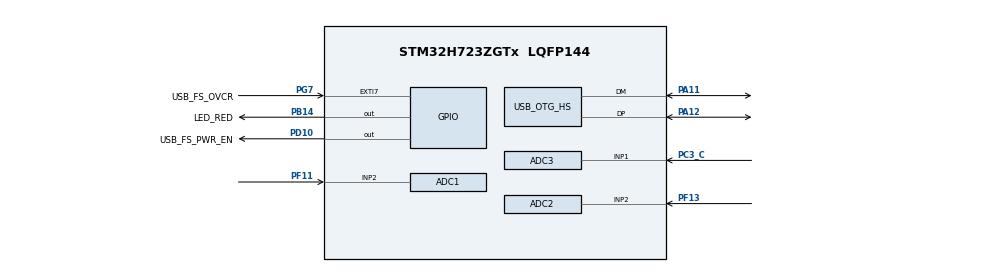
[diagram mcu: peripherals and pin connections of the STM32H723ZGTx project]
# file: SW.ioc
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ADC1.Channel-1\#ChannelRegularConversion=ADC_CHANNEL_2
ADC1.ClockPrescaler=ADC_CLOCK_ASYNC_DIV64
ADC1.NbrOfConversionFlag=1
ADC1.OffsetNumber-1\#ChannelRegularConversion=ADC_OFFSET_NONE
ADC1.OffsetSignedSaturation-1\#ChannelRegularConversion=DISABLE
ADC1.Rank-1\#ChannelRegularConversion=1
ADC1.Resolution=ADC_RESOLUTION_12B
ADC1.SamplingTime-1\#ChannelRegularConversion=ADC_SAMPLETIME_1CYCLE_5
ADC1.master=1
ADC2.Channel-0\#ChannelRegularConversion=ADC_CHANNEL_2
ADC2.ClockPrescaler=ADC_CLOCK_ASYNC_DIV64
ADC2.NbrOfConversionFlag=1
ADC2.OffsetNumber-0\#ChannelRegularConversion=ADC_OFFSET_NONE
ADC2.OffsetSignedSaturation-0\#ChannelRegularConversion=DISABLE
ADC2.Rank-0\#ChannelRegularConversion=1
ADC2.SamplingTime-0\#ChannelRegularConversion=ADC_SAMPLETIME_1CYCLE_5
ADC3.Channel-0\#ChannelRegularConversion=ADC_CHANNEL_1
ADC3.ClockPrescaler=ADC_CLOCK_ASYNC_DIV64
ADC3.NbrOfConversionFlag=1
ADC3.OffsetNumber-0\#ChannelRegularConversion=ADC_OFFSET_NONE
ADC3.OffsetSaturation-0\#ChannelRegularConversion=DISABLE
ADC3.OffsetSign-0\#ChannelRegularConversion=ADC3_OFFSET_SIGN_NEGATIVE
ADC3.OffsetSignedSaturation-0\#ChannelRegularConversion=DISABLE
ADC3.Rank-0\#ChannelRegularConversion=1
ADC3.SamplingTime-0\#ChannelRegularConversion=ADC3_SAMPLETIME_2CYCLES_5
FREERTOS.INCLUDE_uxTaskPriorityGet=0
FREERTOS.INCLUDE_vTaskDelete=0
FREERTOS.INCLUDE_vTaskPrioritySet=0
FREERTOS.MEMORY_ALLOCATION=0
FREERTOS.Tasks01=defaultTask,0,128,StartDefaultTask,Default,NULL,Dynamic,NULL,NULL
FREERTOS.configMAX_PRIORITIES=5
FREERTOS.configUSE_NEWLIB_REENTRANT=1
Mcu.Family=STM32H7
Mcu.Name=STM32H723ZGTx
Mcu.Package=LQFP144
NVIC.OTG_HS_IRQn=true\:5\:0\:false\:false\:true\:true\:false\:true
NVIC.PriorityGroup=NVIC_PRIORITYGROUP_4
NVIC.TIM6_DAC_IRQn=true\:5\:0\:false\:false\:true\:true\:true\:true
NVIC.TIM7_IRQn=true\:15\:0\:false\:false\:true\:false\:false\:true
NVIC.TimeBase=TIM7_IRQn
NVIC.TimeBaseIP=TIM7
PA1.GPIO_Label=RMII_REF_CLK
PA1.Signal=ETH_REF_CLK
PA10.GPIO_Label=USB_FS_ID
PA10.Signal=USB_OTG_HS_ID
PA11.Mode=Device_Only_FS
PA11.Signal=USB_OTG_HS_DM
PA12.Mode=Device_Only_FS
PA12.Signal=USB_OTG_HS_DP
PA13(JTMS/SWDIO).GPIO_Label=SWDIO
PA13(JTMS/SWDIO).Mode=Trace_Asynchronous_SW
PA13(JTMS/SWDIO).Signal=DEBUG_JTMS-SWDIO
PA14(JTCK/SWCLK).GPIO_Label=SWCLK
PA14(JTCK/SWCLK).Mode=Trace_Asynchronous_SW
PA14(JTCK/SWCLK).Signal=DEBUG_JTCK-SWCLK
PA2.GPIO_Label=RMII_MDIO
PA2.Signal=ETH_MDIO
PA7.GPIO_Label=RMII_CRS_DV
PA7.Signal=ETH_CRS_DV
PA9.GPIO_Label=USB_FS_VBUS
PA9.Signal=USB_OTG_HS_VBUS
PB13.GPIO_Label=RMII_TXD1
PB13.Signal=ETH_TXD1
PB14.GPIO_Label=LED_RED
PB14.Signal=GPIO_Output
PB3(JTDO/TRACESWO).GPIO_Label=SWO
PB3(JTDO/TRACESWO).Mode=Trace_Asynchronous_SW
PB3(JTDO/TRACESWO).Signal=DEBUG_JTDO-SWO
PC1.GPIO_Label=RMII_MDC
PC1.Signal=ETH_MDC
PC14-OSC32_IN.Mode=LSE-External-Oscillator
PC14-OSC32_IN.Signal=RCC_OSC32_IN
PC15-OSC32_OUT.Mode=LSE-External-Oscillator
PC15-OSC32_OUT.Signal=RCC_OSC32_OUT
PC3_C.Mode=IN1-Single-Ended
PC3_C.Signal=ADC3_INP1
PC4.GPIO_Label=RMII_RXD0
PC4.Signal=ETH_RXD0
PC5.GPIO_Label=RMII_RXD1
PC5.Signal=ETH_RXD1
PD10.GPIO_Label=USB_FS_PWR_EN
PD10.Signal=GPIO_Output
PD8.GPIO_Label=STLK_VCP_RX
PD8.Signal=USART3_TX
PD9.GPIO_Label=STLK_VCP_TX
PD9.Signal=USART3_RX
PF11.Mode=IN2-Single-Ended
PF11.Signal=ADC1_INP2
PF13.Mode=IN2-Single-Ended
PF13.Signal=ADC2_INP2
PG11.GPIO_Label=RMII_TX_EN
PG11.Signal=ETH_TX_EN
PG13.GPIO_Label=RMII_TXD0
PG13.Signal=ETH_TXD0
PG7.GPIO_Label=USB_FS_OVCR
PG7.Signal=GPXTI7
PH0-OSC_IN.GPIO_Label=MCO
PH0-OSC_IN.Mode=HSE-External-Clock-Source
PH0-OSC_IN.Signal=RCC_OSC_IN
PH1-OSC_OUT.Signal=RCC_OSC_OUT
ProjectManager.HeapSize=0x200
ProjectManager.StackSize=0x400
ProjectManager.TargetToolchain=STM32CubeIDE
RCC.ADCFreq_Value=48000000
RCC.APB1Freq_Value=48000000
RCC.APB2Freq_Value=48000000
RCC.APB3Freq_Value=48000000
RCC.APB4Freq_Value=48000000
RCC.CortexFreq_Value=192000000
RCC.D1PPRE=RCC_APB3_DIV2
RCC.D2PPRE1=RCC_APB1_DIV2
RCC.D2PPRE2=RCC_APB2_DIV2
RCC.D3PPRE=RCC_APB4_DIV2
RCC.DIVM1=1
RCC.DIVM2=1
RCC.DIVN1=24
RCC.DIVN2=24
RCC.DIVP1=1
RCC.DIVP2=4
RCC.DIVQ1=4
RCC.HCLKFreq_Value=96000000
RCC.HPRE=RCC_HCLK_DIV2
RCC.HSE_VALUE=8000000
RCC.PLL2FRACN=0
RCC.PLLFRACN=0
RCC.PLLSourceVirtual=RCC_PLLSOURCE_HSE
RCC.SYSCLKFreq_VALUE=192000000
RCC.SYSCLKSource=RCC_SYSCLKSOURCE_PLLCLK
RCC.USBCLockSelection=RCC_USBCLKSOURCE_HSI48
RCC.USBFreq_Value=48000000
TIM6.AutoReloadPreload=TIM_AUTORELOAD_PRELOAD_ENABLE
TIM6.Period=31999
TIM6.Prescaler=2999
USB_DEVICE.CLASS_NAME_HS=CDC
USB_DEVICE.VirtualMode=Cdc
USB_DEVICE.VirtualModeHS=Cdc_HS
USB_OTG_HS.VirtualMode-Device_Only_FS=Device_Only_FS
VP_FREERTOS_VS_CMSIS_V1.Mode=CMSIS_V1
VP_SYS_VS_tim7.Mode=TIM7
VP_TIM6_VS_ClockSourceINT.Mode=Enable_Timer
VP_USB_DEVICE_VS_USB_DEVICE_CDC_HS.Mode=CDC_HS
board=NUCLEO-H723ZG

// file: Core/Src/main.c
/* USER CODE BEGIN Header */
/**
  ******************************************************************************
  * @file           : main.c
  * @brief          : Main program body
  ******************************************************************************
  * @attention
  *
  * <h2><center>&copy; Copyright (c) 2021 STMicroelectronics.
  * All rights reserved.</center></h2>
  *
  * This software component is licensed by ST under Ultimate Liberty license
  * SLA0044, the "License"; You may not use this file except in compliance with
  * the License. You may obtain a copy of the License at:
  *                             www.st.com/SLA0044
  *
  ******************************************************************************
  */
/* USER CODE END Header */
#include "main.h"
#include "cmsis_os.h"
#include "usb_device.h"

/* USER CODE BEGIN Includes */
#include "voltmeter.h"
/* USER CODE END Includes */

ADC_HandleTypeDef hadc1;
ADC_HandleTypeDef hadc2;
ADC_HandleTypeDef hadc3;

TIM_HandleTypeDef htim6;

osThreadId defaultTaskHandle;

/* USER CODE BEGIN PV */

//TaskHandle_t* HandleTask1;

/* USER CODE END PV */

void SystemClock_Config(void);
void PeriphCommonClock_Config(void);
static void MX_GPIO_Init(void);
static void MX_ADC1_Init(void);
static void MX_ADC2_Init(void);
static void MX_ADC3_Init(void);
static void MX_TIM6_Init(void);
void StartDefaultTask(void const * argument);

int main(void)
{

  /* MCU Configuration--------------------------------------------------------*/

  /* Reset of all peripherals, Initializes the Flash interface and the Systick. */
  HAL_Init();

  /* Configure the system clock */
  SystemClock_Config();

/* Configure the peripherals common clocks */
  PeriphCommonClock_Config();

  /* Initialize all configured peripherals */
  MX_GPIO_Init();
  MX_ADC1_Init();
  MX_ADC2_Init();
  MX_ADC3_Init();
  MX_TIM6_Init();
  /* USER CODE BEGIN 2 */

  Voltmeter_init();

  /* USER CODE END 2 */

  /* Create the thread(s) */
  /* definition and creation of defaultTask */
  osThreadDef(defaultTask, StartDefaultTask, osPriorityNormal, 0, 128);
  defaultTaskHandle = osThreadCreate(osThread(defaultTask), NULL);

  /* USER CODE BEGIN RTOS_THREADS */
  vTaskStartScheduler();
  /* USER CODE END RTOS_THREADS */

  /* Start scheduler */
  //osKernelStart();

  /* We should never get here as control is now taken by the scheduler */
  /* Infinite loop */
  while (1)
  {

  }
}

void SystemClock_Config(void)
{
  RCC_OscInitTypeDef RCC_OscInitStruct = {0};
  RCC_ClkInitTypeDef RCC_ClkInitStruct = {0};

  /** Supply configuration update enable
  */
  HAL_PWREx_ConfigSupply(PWR_LDO_SUPPLY);
  /** Configure the main internal regulator output voltage
  */
  __HAL_PWR_VOLTAGESCALING_CONFIG(PWR_REGULATOR_VOLTAGE_SCALE2);

  while(!__HAL_PWR_GET_FLAG(PWR_FLAG_VOSRDY)) {}
  /** Macro to configure the PLL clock source
  */
  __HAL_RCC_PLL_PLLSOURCE_CONFIG(RCC_PLLSOURCE_HSE);
  /** Initializes the RCC Oscillators according to the specified parameters
  * in the RCC_OscInitTypeDef structure.
  */
  RCC_OscInitStruct.OscillatorType = RCC_OSCILLATORTYPE_HSI48|RCC_OSCILLATORTYPE_HSE;
  RCC_OscInitStruct.HSEState = RCC_HSE_BYPASS;
  RCC_OscInitStruct.HSI48State = RCC_HSI48_ON;
  RCC_OscInitStruct.PLL.PLLState = RCC_PLL_ON;
  RCC_OscInitStruct.PLL.PLLSource = RCC_PLLSOURCE_HSE;
  RCC_OscInitStruct.PLL.PLLM = 1;
  RCC_OscInitStruct.PLL.PLLN = 24;
  RCC_OscInitStruct.PLL.PLLP = 1;
  RCC_OscInitStruct.PLL.PLLQ = 4;
  RCC_OscInitStruct.PLL.PLLR = 2;
  RCC_OscInitStruct.PLL.PLLRGE = RCC_PLL1VCIRANGE_3;
  RCC_OscInitStruct.PLL.PLLVCOSEL = RCC_PLL1VCOWIDE;
  RCC_OscInitStruct.PLL.PLLFRACN = 0;
  if (HAL_RCC_OscConfig(&RCC_OscInitStruct) != HAL_OK)
  {
    Error_Handler();
  }
  /** Initializes the CPU, AHB and APB buses clocks
  */
  RCC_ClkInitStruct.ClockType = RCC_CLOCKTYPE_HCLK|RCC_CLOCKTYPE_SYSCLK
                              |RCC_CLOCKTYPE_PCLK1|RCC_CLOCKTYPE_PCLK2
                              |RCC_CLOCKTYPE_D3PCLK1|RCC_CLOCKTYPE_D1PCLK1;
  RCC_ClkInitStruct.SYSCLKSource = RCC_SYSCLKSOURCE_PLLCLK;
  RCC_ClkInitStruct.SYSCLKDivider = RCC_SYSCLK_DIV1;
  RCC_ClkInitStruct.AHBCLKDivider = RCC_HCLK_DIV2;
  RCC_ClkInitStruct.APB3CLKDivider = RCC_APB3_DIV2;
  RCC_ClkInitStruct.APB1CLKDivider = RCC_APB1_DIV2;
  RCC_ClkInitStruct.APB2CLKDivider = RCC_APB2_DIV2;
  RCC_ClkInitStruct.APB4CLKDivider = RCC_APB4_DIV2;

  if (HAL_RCC_ClockConfig(&RCC_ClkInitStruct, FLASH_LATENCY_1) != HAL_OK)
  {
    Error_Handler();
  }
}

void PeriphCommonClock_Config(void)
{
  RCC_PeriphCLKInitTypeDef PeriphClkInitStruct = {0};

  /** Initializes the peripherals clock
  */
  PeriphClkInitStruct.PeriphClockSelection = RCC_PERIPHCLK_ADC;
  PeriphClkInitStruct.PLL2.PLL2M = 1;
  PeriphClkInitStruct.PLL2.PLL2N = 24;
  PeriphClkInitStruct.PLL2.PLL2P = 4;
  PeriphClkInitStruct.PLL2.PLL2Q = 2;
  PeriphClkInitStruct.PLL2.PLL2R = 2;
  PeriphClkInitStruct.PLL2.PLL2RGE = RCC_PLL2VCIRANGE_3;
  PeriphClkInitStruct.PLL2.PLL2VCOSEL = RCC_PLL2VCOWIDE;
  PeriphClkInitStruct.PLL2.PLL2FRACN = 0;
  PeriphClkInitStruct.AdcClockSelection = RCC_ADCCLKSOURCE_PLL2;
  if (HAL_RCCEx_PeriphCLKConfig(&PeriphClkInitStruct) != HAL_OK)
  {
    Error_Handler();
  }
}

static void MX_ADC1_Init(void)
{

  ADC_MultiModeTypeDef multimode = {0};
  ADC_ChannelConfTypeDef sConfig = {0};

  /** Common config
  */
  hadc1.Instance = ADC1;
  hadc1.Init.ClockPrescaler = ADC_CLOCK_ASYNC_DIV64;
  hadc1.Init.Resolution = ADC_RESOLUTION_12B;
  hadc1.Init.ScanConvMode = ADC_SCAN_DISABLE;
  hadc1.Init.EOCSelection = ADC_EOC_SINGLE_CONV;
  hadc1.Init.LowPowerAutoWait = DISABLE;
  hadc1.Init.ContinuousConvMode = DISABLE;
  hadc1.Init.NbrOfConversion = 1;
  hadc1.Init.DiscontinuousConvMode = DISABLE;
  hadc1.Init.ExternalTrigConv = ADC_SOFTWARE_START;
  hadc1.Init.ExternalTrigConvEdge = ADC_EXTERNALTRIGCONVEDGE_NONE;
  hadc1.Init.ConversionDataManagement = ADC_CONVERSIONDATA_DR;
  hadc1.Init.Overrun = ADC_OVR_DATA_PRESERVED;
  hadc1.Init.LeftBitShift = ADC_LEFTBITSHIFT_NONE;
  hadc1.Init.OversamplingMode = DISABLE;
  if (HAL_ADC_Init(&hadc1) != HAL_OK)
  {
    Error_Handler();
  }
  /** Configure the ADC multi-mode
  */
  multimode.Mode = ADC_MODE_INDEPENDENT;
  if (HAL_ADCEx_MultiModeConfigChannel(&hadc1, &multimode) != HAL_OK)
  {
    Error_Handler();
  }
  /** Configure Regular Channel
  */
  sConfig.Channel = ADC_CHANNEL_2;
  sConfig.Rank = ADC_REGULAR_RANK_1;
  sConfig.SamplingTime = ADC_SAMPLETIME_1CYCLE_5;
  sConfig.SingleDiff = ADC_SINGLE_ENDED;
  sConfig.OffsetNumber = ADC_OFFSET_NONE;
  sConfig.Offset = 0;
  sConfig.OffsetSignedSaturation = DISABLE;
  if (HAL_ADC_ConfigChannel(&hadc1, &sConfig) != HAL_OK)
  {
    Error_Handler();
  }

}

static void MX_ADC2_Init(void)
{

  ADC_ChannelConfTypeDef sConfig = {0};

  /** Common config
  */
  hadc2.Instance = ADC2;
  hadc2.Init.ClockPrescaler = ADC_CLOCK_ASYNC_DIV64;
  hadc2.Init.Resolution = ADC_RESOLUTION_16B;
  hadc2.Init.ScanConvMode = ADC_SCAN_DISABLE;
  hadc2.Init.EOCSelection = ADC_EOC_SINGLE_CONV;
  hadc2.Init.LowPowerAutoWait = DISABLE;
  hadc2.Init.ContinuousConvMode = DISABLE;
  hadc2.Init.NbrOfConversion = 1;
  hadc2.Init.DiscontinuousConvMode = DISABLE;
  hadc2.Init.ExternalTrigConv = ADC_SOFTWARE_START;
  hadc2.Init.ExternalTrigConvEdge = ADC_EXTERNALTRIGCONVEDGE_NONE;
  hadc2.Init.ConversionDataManagement = ADC_CONVERSIONDATA_DR;
  hadc2.Init.Overrun = ADC_OVR_DATA_PRESERVED;
  hadc2.Init.LeftBitShift = ADC_LEFTBITSHIFT_NONE;
  hadc2.Init.OversamplingMode = DISABLE;
  if (HAL_ADC_Init(&hadc2) != HAL_OK)
  {
    Error_Handler();
  }
  /** Configure Regular Channel
  */
  sConfig.Channel = ADC_CHANNEL_2;
  sConfig.Rank = ADC_REGULAR_RANK_1;
  sConfig.SamplingTime = ADC_SAMPLETIME_1CYCLE_5;
  sConfig.SingleDiff = ADC_SINGLE_ENDED;
  sConfig.OffsetNumber = ADC_OFFSET_NONE;
  sConfig.Offset = 0;
  sConfig.OffsetSignedSaturation = DISABLE;
  if (HAL_ADC_ConfigChannel(&hadc2, &sConfig) != HAL_OK)
  {
    Error_Handler();
  }

}

static void MX_ADC3_Init(void)
{

  ADC_ChannelConfTypeDef sConfig = {0};

  /** Common config
  */
  hadc3.Instance = ADC3;
  hadc3.Init.ClockPrescaler = ADC_CLOCK_ASYNC_DIV64;
  hadc3.Init.Resolution = ADC_RESOLUTION_12B;
  hadc3.Init.DataAlign = ADC3_DATAALIGN_RIGHT;
  hadc3.Init.ScanConvMode = ADC_SCAN_DISABLE;
  hadc3.Init.EOCSelection = ADC_EOC_SINGLE_CONV;
  hadc3.Init.LowPowerAutoWait = DISABLE;
  hadc3.Init.ContinuousConvMode = DISABLE;
  hadc3.Init.NbrOfConversion = 1;
  hadc3.Init.DiscontinuousConvMode = DISABLE;
  hadc3.Init.ExternalTrigConv = ADC_SOFTWARE_START;
  hadc3.Init.ExternalTrigConvEdge = ADC_EXTERNALTRIGCONVEDGE_NONE;
  hadc3.Init.DMAContinuousRequests = DISABLE;
  hadc3.Init.SamplingMode = ADC_SAMPLING_MODE_NORMAL;
  hadc3.Init.ConversionDataManagement = ADC_CONVERSIONDATA_DR;
  hadc3.Init.Overrun = ADC_OVR_DATA_PRESERVED;
  hadc3.Init.LeftBitShift = ADC_LEFTBITSHIFT_NONE;
  hadc3.Init.OversamplingMode = DISABLE;
  if (HAL_ADC_Init(&hadc3) != HAL_OK)
  {
    Error_Handler();
  }
  /** Configure Regular Channel
  */
  sConfig.Channel = ADC_CHANNEL_1;
  sConfig.Rank = ADC_REGULAR_RANK_1;
  sConfig.SamplingTime = ADC3_SAMPLETIME_2CYCLES_5;
  sConfig.SingleDiff = ADC_SINGLE_ENDED;
  sConfig.OffsetNumber = ADC_OFFSET_NONE;
  sConfig.Offset = 0;
  sConfig.OffsetSignedSaturation = DISABLE;
  sConfig.OffsetSign = ADC3_OFFSET_SIGN_NEGATIVE;
  sConfig.OffsetSaturation = DISABLE;
  if (HAL_ADC_ConfigChannel(&hadc3, &sConfig) != HAL_OK)
  {
    Error_Handler();
  }

}

static void MX_TIM6_Init(void)
{

  TIM_MasterConfigTypeDef sMasterConfig = {0};

  htim6.Instance = TIM6;
  htim6.Init.Prescaler = 2999;
  htim6.Init.CounterMode = TIM_COUNTERMODE_UP;
  htim6.Init.Period = 31999;
  htim6.Init.AutoReloadPreload = TIM_AUTORELOAD_PRELOAD_ENABLE;
  if (HAL_TIM_Base_Init(&htim6) != HAL_OK)
  {
    Error_Handler();
  }
  sMasterConfig.MasterOutputTrigger = TIM_TRGO_RESET;
  sMasterConfig.MasterSlaveMode = TIM_MASTERSLAVEMODE_DISABLE;
  if (HAL_TIMEx_MasterConfigSynchronization(&htim6, &sMasterConfig) != HAL_OK)
  {
    Error_Handler();
  }

}

static void MX_GPIO_Init(void)
{
  GPIO_InitTypeDef GPIO_InitStruct = {0};

  /* GPIO Ports Clock Enable */
  __HAL_RCC_GPIOC_CLK_ENABLE();
  __HAL_RCC_GPIOH_CLK_ENABLE();
  __HAL_RCC_GPIOA_CLK_ENABLE();
  __HAL_RCC_GPIOF_CLK_ENABLE();
  __HAL_RCC_GPIOB_CLK_ENABLE();
  __HAL_RCC_GPIOD_CLK_ENABLE();
  __HAL_RCC_GPIOG_CLK_ENABLE();

  /*Configure GPIO pin Output Level */
  HAL_GPIO_WritePin(LED_RED_GPIO_Port, LED_RED_Pin, GPIO_PIN_RESET);

  /*Configure GPIO pin Output Level */
  HAL_GPIO_WritePin(USB_FS_PWR_EN_GPIO_Port, USB_FS_PWR_EN_Pin, GPIO_PIN_RESET);

  /*Configure GPIO pins : RMII_MDC_Pin RMII_RXD0_Pin RMII_RXD1_Pin */
  GPIO_InitStruct.Pin = RMII_MDC_Pin|RMII_RXD0_Pin|RMII_RXD1_Pin;
  GPIO_InitStruct.Mode = GPIO_MODE_AF_PP;
  GPIO_InitStruct.Pull = GPIO_NOPULL;
  GPIO_InitStruct.Speed = GPIO_SPEED_FREQ_LOW;
  GPIO_InitStruct.Alternate = GPIO_AF11_ETH;
  HAL_GPIO_Init(GPIOC, &GPIO_InitStruct);

  /*Configure GPIO pins : RMII_REF_CLK_Pin RMII_MDIO_Pin RMII_CRS_DV_Pin */
  GPIO_InitStruct.Pin = RMII_REF_CLK_Pin|RMII_MDIO_Pin|RMII_CRS_DV_Pin;
  GPIO_InitStruct.Mode = GPIO_MODE_AF_PP;
  GPIO_InitStruct.Pull = GPIO_NOPULL;
  GPIO_InitStruct.Speed = GPIO_SPEED_FREQ_LOW;
  GPIO_InitStruct.Alternate = GPIO_AF11_ETH;
  HAL_GPIO_Init(GPIOA, &GPIO_InitStruct);

  /*Configure GPIO pin : RMII_TXD1_Pin */
  GPIO_InitStruct.Pin = RMII_TXD1_Pin;
  GPIO_InitStruct.Mode = GPIO_MODE_AF_PP;
  GPIO_InitStruct.Pull = GPIO_NOPULL;
  GPIO_InitStruct.Speed = GPIO_SPEED_FREQ_LOW;
  GPIO_InitStruct.Alternate = GPIO_AF11_ETH;
  HAL_GPIO_Init(RMII_TXD1_GPIO_Port, &GPIO_InitStruct);

  /*Configure GPIO pin : LED_RED_Pin */
  GPIO_InitStruct.Pin = LED_RED_Pin;
  GPIO_InitStruct.Mode = GPIO_MODE_OUTPUT_PP;
  GPIO_InitStruct.Pull = GPIO_NOPULL;
  GPIO_InitStruct.Speed = GPIO_SPEED_FREQ_LOW;
  HAL_GPIO_Init(LED_RED_GPIO_Port, &GPIO_InitStruct);

  /*Configure GPIO pins : STLK_VCP_RX_Pin STLK_VCP_TX_Pin */
  GPIO_InitStruct.Pin = STLK_VCP_RX_Pin|STLK_VCP_TX_Pin;
  GPIO_InitStruct.Mode = GPIO_MODE_AF_PP;
  GPIO_InitStruct.Pull = GPIO_NOPULL;
  GPIO_InitStruct.Speed = GPIO_SPEED_FREQ_LOW;
  GPIO_InitStruct.Alternate = GPIO_AF7_USART3;
  HAL_GPIO_Init(GPIOD, &GPIO_InitStruct);

  /*Configure GPIO pin : USB_FS_PWR_EN_Pin */
  GPIO_InitStruct.Pin = USB_FS_PWR_EN_Pin;
  GPIO_InitStruct.Mode = GPIO_MODE_OUTPUT_PP;
  GPIO_InitStruct.Pull = GPIO_NOPULL;
  GPIO_InitStruct.Speed = GPIO_SPEED_FREQ_LOW;
  HAL_GPIO_Init(USB_FS_PWR_EN_GPIO_Port, &GPIO_InitStruct);

  /*Configure GPIO pin : USB_FS_OVCR_Pin */
  GPIO_InitStruct.Pin = USB_FS_OVCR_Pin;
  GPIO_InitStruct.Mode = GPIO_MODE_IT_RISING;
  GPIO_InitStruct.Pull = GPIO_NOPULL;
  HAL_GPIO_Init(USB_FS_OVCR_GPIO_Port, &GPIO_InitStruct);

  /*Configure GPIO pins : RMII_TX_EN_Pin RMII_TXD0_Pin */
  GPIO_InitStruct.Pin = RMII_TX_EN_Pin|RMII_TXD0_Pin;
  GPIO_InitStruct.Mode = GPIO_MODE_AF_PP;
  GPIO_InitStruct.Pull = GPIO_NOPULL;
  GPIO_InitStruct.Speed = GPIO_SPEED_FREQ_LOW;
  GPIO_InitStruct.Alternate = GPIO_AF11_ETH;
  HAL_GPIO_Init(GPIOG, &GPIO_InitStruct);

}

void StartDefaultTask(void const * argument)
{
  /* init code for USB_DEVICE */
  MX_USB_DEVICE_Init();
  for(;;)
  {
    osDelay(1);
  }
}

void HAL_TIM_PeriodElapsedCallback(TIM_HandleTypeDef *htim)
{
  if (htim->Instance == TIM7) {
    HAL_IncTick();
  }
}

void Error_Handler(void)
{
  __disable_irq();
  while (1)
  {
  }
}

/************************ (C) COPYRIGHT STMicroelectronics *****END OF FILE****/
